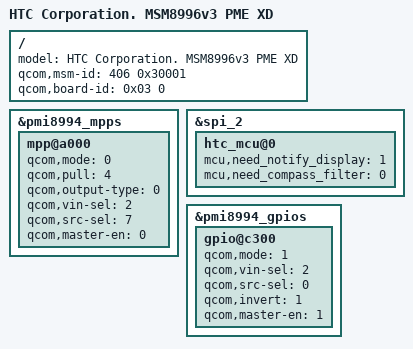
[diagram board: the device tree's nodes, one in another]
/* Copyright (c) 2015, The Linux Foundation. All rights reserved.
 *
 * This program is free software; you can redistribute it and/or modify
 * it under the terms of the GNU General Public License version 2 and
 * only version 2 as published by the Free Software Foundation.
 *
 * This program is distributed in the hope that it will be useful,
 * but WITHOUT ANY WARRANTY; without even the implied warranty of
 * MERCHANTABILITY or FITNESS FOR A PARTICULAR PURPOSE.  See the
 * GNU General Public License for more details.
 */


/dts-v1/;

#include "msm8996-v3.dtsi"
#include "msm-pmi8996.dtsi"
#include "msm8996-htc_pme.dtsi"
#include "msm8996-camera-sensor-pme_xc.dtsi"
#include "msm8996-charger-pme_xc.dtsi"

/ {
	model = "HTC Corporation. MSM8996v3 PME XD";
	qcom,msm-id = <406 0x30001>;
	qcom,board-id = <0x03 0>;
};

&pmi8994_mpps {
        mpp@a000 { /* MPP 1 */
                qcom,mode = <0>;                /* Digital input */
                qcom,pull = <4>;                /* Pull down */
                qcom,output-type = <0>;         /* CMOS logic */
                qcom,vin-sel = <2>;             /* S4 1.8V */
                qcom,src-sel = <7>;             /* DTEST4 */
                qcom,master-en = <0>;           /* Disable MPP */
                status = "okay";
        };
};

&spi_2 {
        htc_mcu@0 {
                mcu,need_notify_display = <1>;
                mcu,need_compass_filter = <0>;
        };
};

&pmi8994_gpios {
	gpio@c300 {     /* GPIO 4, vddio_en, 1.8V boost  */
		qcom,mode = <1>;
		qcom,vin-sel = <2>;
		qcom,src-sel = <0>;
		qcom,invert = <1>;   /* need invert = 0 */
		qcom,master-en = <1>;
		status = "okay";
	};
};
